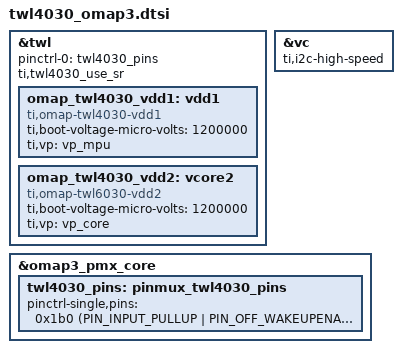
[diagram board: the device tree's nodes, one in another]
/*
 * Copyright (C) 2013 Linaro, Ltd.
 *
 * This program is free software; you can redistribute it and/or modify
 * it under the terms of the GNU General Public License version 2 as
 * published by the Free Software Foundation.
 */

&twl {
	pinctrl-names = "default";
	pinctrl-0 = <&twl4030_pins>;

	ti,twl4030_use_sr;

	omap_twl4030_vdd1: vdd1 {
		compatible = "ti,omap-twl4030-vdd1";
		ti,boot-voltage-micro-volts = <1200000>; /* TBD: verify */
		ti,vp = <&vp_mpu>;
	};

	omap_twl4030_vdd2: vcore2 {
		compatible = "ti,omap-twl6030-vdd2";
		ti,boot-voltage-micro-volts = <1200000>; /* TBD: verify */
		ti,vp = <&vp_core>;
	};
};

&vc {
	ti,i2c-high-speed;
};

&omap3_pmx_core {
	/*
	 * On most OMAP3 platforms, the twl4030 IRQ line is connected
	 * to the SYS_NIRQ line on OMAP.  Therefore, configure the
	 * defaults for the SYS_NIRQ pin here.
	 */
	twl4030_pins: pinmux_twl4030_pins {
		pinctrl-single,pins = <
			0x1b0 (PIN_INPUT_PULLUP | PIN_OFF_WAKEUPENABLE | MUX_MODE0) /* sys_nirq.sys_nirq */
		>;
	};
};
